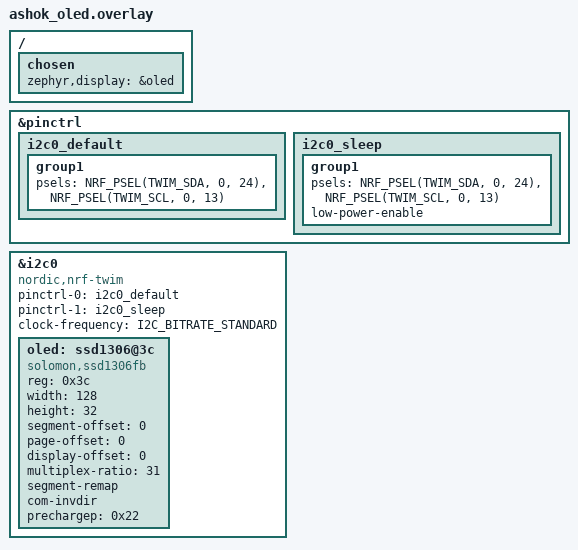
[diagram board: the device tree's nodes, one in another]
/*
 * Custom OLED shield for Ashok's macropad
 * Uses specific I2C pins: P0.24 (SDA), P0.13 (SCL)
 */

#include <zephyr/dt-bindings/gpio/gpio.h>
#include <zephyr/dt-bindings/i2c/i2c.h>

/ {
    chosen {
        zephyr,display = &oled;
    };
};

&pinctrl {
    i2c0_default: i2c0_default {
        group1 {
            psels = <NRF_PSEL(TWIM_SDA, 0, 24)>,   /* P0.24 - SDA */
                    <NRF_PSEL(TWIM_SCL, 0, 13)>;   /* P0.13 - SCL */
        };
    };

    i2c0_sleep: i2c0_sleep {
        group1 {
            psels = <NRF_PSEL(TWIM_SDA, 0, 24)>,   /* P0.24 - SDA */
                    <NRF_PSEL(TWIM_SCL, 0, 13)>;   /* P0.13 - SCL */
            low-power-enable;
        };
    };
};

&i2c0 {
    compatible = "nordic,nrf-twim";
    status = "okay";
    
    pinctrl-0 = <&i2c0_default>;
    pinctrl-1 = <&i2c0_sleep>;
    pinctrl-names = "default", "sleep";
    
    clock-frequency = <I2C_BITRATE_STANDARD>;

    oled: ssd1306@3c {
        compatible = "solomon,ssd1306fb";
        reg = <0x3c>;
        width = <128>;
        height = <32>;
        segment-offset = <0>;
        page-offset = <0>;
        display-offset = <0>;
        multiplex-ratio = <31>;
        segment-remap;
        com-invdir;
        prechargep = <0x22>;
    };
};
